# AS32x601 register map
File version: 1.0
CPU: RISC-V, little endian
Registers are 32-bit, read-write, reset 0x0 unless marked. A register's access mark holds for its fields unless they carry their own. Offsets are from the block's base; [hi:lo] are bit positions; {n}, {i} and the like mark numbered series.

## GPIOA — General-purpose I/Os
Base 0x41004000
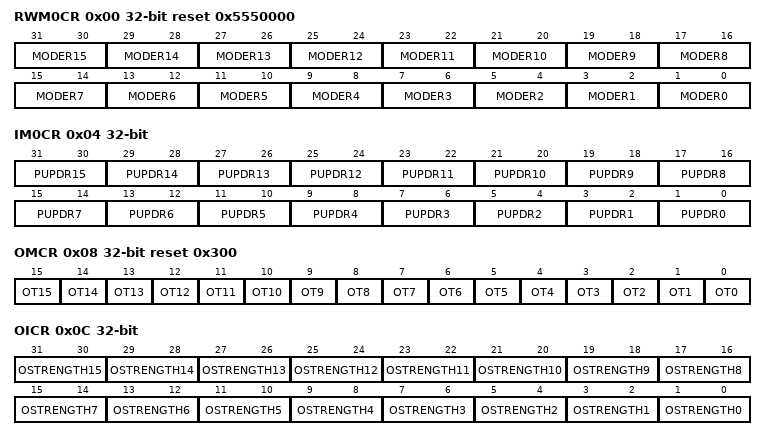
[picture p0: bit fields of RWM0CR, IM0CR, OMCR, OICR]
0x00 RWM0CR reset 0x5550000 — Read/write mode control register 0
  [2n+1:2n] MODER{n} (n=0..15) — Control the read and write mode of Control {n}
0x04 IM0CR — Input mode control register 0
  [2n+1:2n] PUPDR{n} (n=0..15) — Channel {n} input mode control
0x08 OMCR reset 0x300 — Output mode control register
  [n] OT{n} (n=0..15) — Channel {n} output mode control
0x0C OICR — Output intensity control register 0
  [2n+1:2n] OSTRENGTH{n} (n=0..15) — Channel {n} output strength control
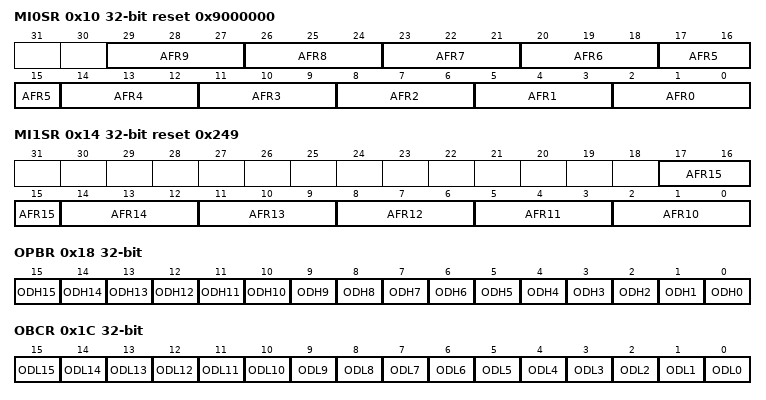
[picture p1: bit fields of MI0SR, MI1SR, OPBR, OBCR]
0x10 MI0SR reset 0x9000000 — Multiplex interface select register 0
  [3n+2:3n] AFR{n} (n=0..9) — Channel {n} multiplexing interface selection
0x14 MI1SR reset 0x249 — Multiplex interface select register 1
  [3n-28:3n-30] AFR{n} (n=10..15) — Channel {n} multiplexing interface selection
0x18 OPBR wo — Output position bit register
  [n] ODH{n} (n=0..15) — Channel {n} output set
0x1C OBCR wo — Output bit clear register
  [n] ODL{n} (n=0..15) — Channel {n} output clear
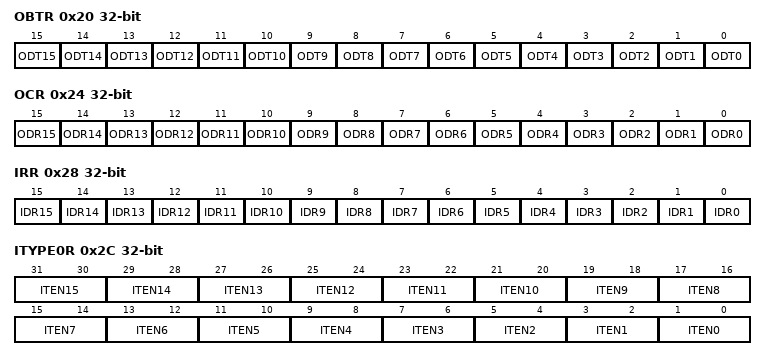
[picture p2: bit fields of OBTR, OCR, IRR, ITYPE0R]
0x20 OBTR wo — Output bit flip register
  [n] ODT{n} (n=0..15) — Channel {n} output toggle
0x24 OCR — Output control register
  [n] ODR{n} (n=0..15) — Channel {n} output control
0x28 IRR ro — Read interface register
  [n] IDR{n} (n=0..15) — Channel {n} input read
0x2C ITYPE0R — Interrupt type register 0
  [2n+1:2n] ITEN{n} (n=0..15) — Select the channel {n} interrupt type
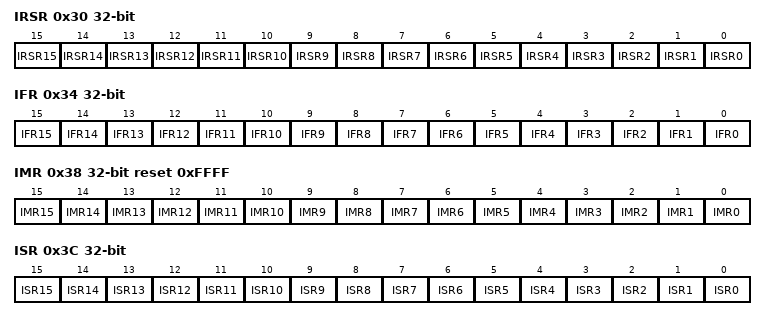
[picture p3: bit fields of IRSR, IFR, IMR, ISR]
0x30 IRSR — Interrupt Raw status Register
  [n] IRSR{n} (n=0..15) — Interrupt Raw status of channel {n}
0x34 IFR — Interrupt Force Register
  [n] IFR{n} (n=0..15) — Channel {n} interrupt force
0x38 IMR reset 0xFFFF — Interrupt Mask Register
  [n] IMR{n} (n=0..15) — Channel {n} interrupt mask
0x3C ISR ro — Interrupt status Register
  [n] ISR{n} (n=0..15) — Channel {n} interrupt status

## GPIOB — General-purpose I/Os
Base 0x41005000
Registers as GPIOA; these are added or differ:
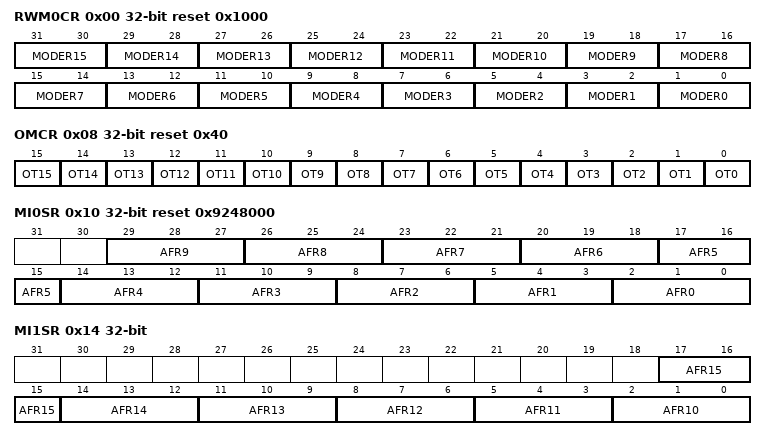
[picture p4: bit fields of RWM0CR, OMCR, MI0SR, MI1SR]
0x00 RWM0CR reset 0x1000 — Read/write mode control register 0
  [2n+1:2n] MODER{n} (n=0..15) — Control the read and write mode of Control {n}
0x08 OMCR reset 0x40 — Output mode control register
  [n] OT{n} (n=0..15) — Channel {n} output mode control
0x10 MI0SR reset 0x9248000 — Multiplex interface select register 0
  [3n+2:3n] AFR{n} (n=0..9) — Channel {n} multiplexing interface selection
0x14 MI1SR — Multiplex interface select register 1
  [3n-28:3n-30] AFR{n} (n=10..15) — Channel {n} multiplexing interface selection

## GPIOC — General-purpose I/Os
Base 0x41006000
Registers as GPIOA; these are added or differ:
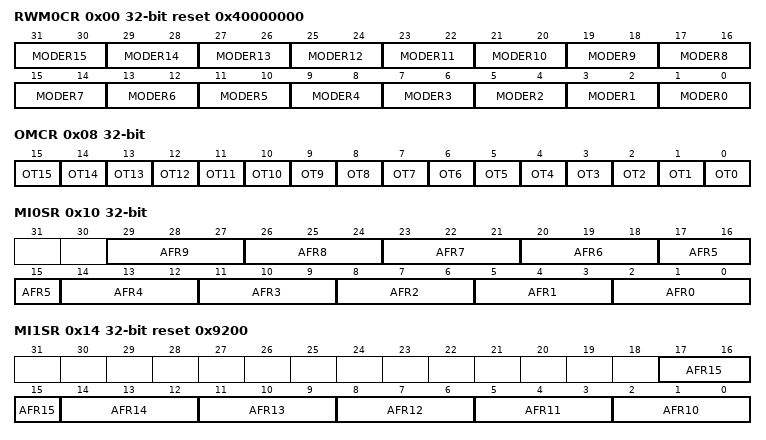
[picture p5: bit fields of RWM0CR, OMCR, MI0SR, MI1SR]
0x00 RWM0CR reset 0x40000000 — Read/write mode control register 0
  [2n+1:2n] MODER{n} (n=0..15) — Control the read and write mode of Control {n}
0x08 OMCR — Output mode control register
  [n] OT{n} (n=0..15) — Channel {n} output mode control
0x10 MI0SR — Multiplex interface select register 0
  [3n+2:3n] AFR{n} (n=0..9) — Channel {n} multiplexing interface selection
0x14 MI1SR reset 0x9200 — Multiplex interface select register 1
  [3n-28:3n-30] AFR{n} (n=10..15) — Channel {n} multiplexing interface selection

## GPIOD — General-purpose I/Os
Base 0x42003000
Same registers: GPIOE 0x42004000, GPIOG 0x42006000
Registers as GPIOC; these are added or differ:
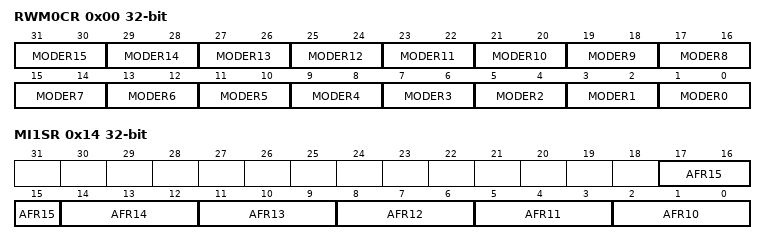
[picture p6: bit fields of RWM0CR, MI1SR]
0x00 RWM0CR — Read/write mode control register 0
  [2n+1:2n] MODER{n} (n=0..15) — Control the read and write mode of Control {n}
0x14 MI1SR — Multiplex interface select register 1
  [3n-28:3n-30] AFR{n} (n=10..15) — Channel {n} multiplexing interface selection

## GPIOF — General-purpose I/Os
Base 0x42005000
Registers as GPIOB; these are added or differ:
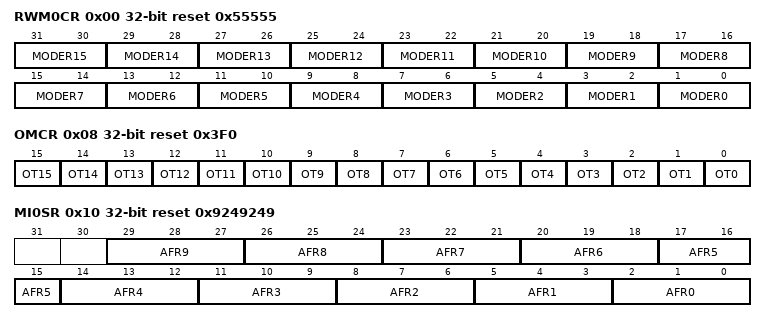
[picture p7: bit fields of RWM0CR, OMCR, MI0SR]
0x00 RWM0CR reset 0x55555 — Read/write mode control register 0
  [2n+1:2n] MODER{n} (n=0..15) — Control the read and write mode of Control {n}
0x08 OMCR reset 0x3F0 — Output mode control register
  [n] OT{n} (n=0..15) — Channel {n} output mode control
0x10 MI0SR reset 0x9249249 — Multiplex interface select register 0
  [3n+2:3n] AFR{n} (n=0..9) — Channel {n} multiplexing interface selection
